# DSP_CM1 register map
Vendor: Texas Instruments
Peripheral module from a debugger description file (folder omap4430).
Registers are 32-bit, access per field, reset 0x3 unless marked. A register's access mark holds for its fields unless they carry their own. Offsets are as the file gives them; lines under a group give offsets from that group; [hi:lo] are bit positions; {n}, {i} and the like mark numbered series; 'fields as' and 'values as' point back to an identical list; <NAME> marks a mode.

## DSP_CM1
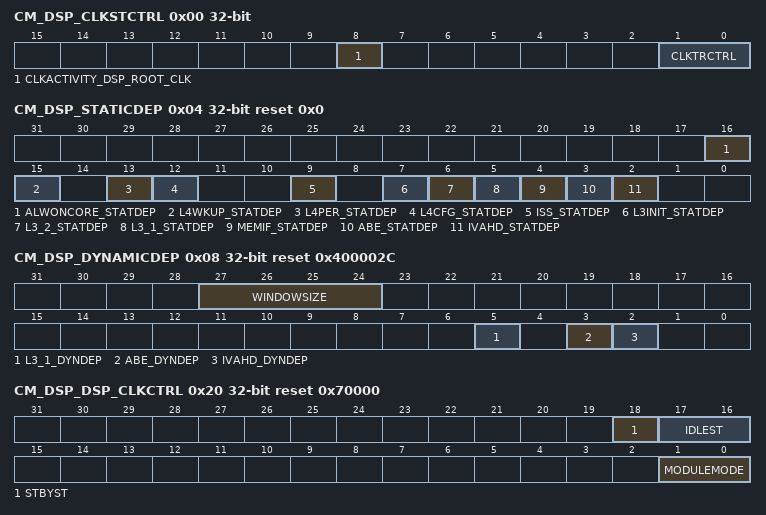
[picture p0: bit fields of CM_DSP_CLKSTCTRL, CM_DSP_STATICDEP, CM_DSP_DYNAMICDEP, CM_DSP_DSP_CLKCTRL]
0x00 CM_DSP_CLKSTCTRL — This register enables the DSP domain power state transition. It controls the hardware supervised domain power state transition between ON-ACTIVE and ON-INACTIVE states. It also holds 1 status bit per clock input of the domain.
  [8] CLKACTIVITY_DSP_ROOT_CLK ro — This field indicates the state of the DSP_ROOT_CLK clock in the domain. [warm reset insensitive]
    0=CLKACTIVITY_DSP_ROOT_CLK_0_r (Corresponding clock is definitely gated); 1=CLKACTIVITY_DSP_ROOT_CLK_1_r (Corresponding clock is running or gating/ungating transition is ongoing)
  [1:0] CLKTRCTRL rw — Controls the clock state transition of the DSP clock domain.
    0=NO_SLEEP: Sleep transition cannot be initiated. Wakeup transition may however occur.; 1=SW_SLEEP: Start a software forced sleep transition on the domain; 2=SW_WKUP: Start a software forced wake-up transition on the domain; 3=HW_AUTO: Automatic transition is enabled. Sleep and wakeup transition are based upon hardware conditions.
0x04 CM_DSP_STATICDEP reset 0x0 — This register controls the static domain depedencies from DSP domain towards 'target' domains. It is relevant only for domain having system initiator(s).
  [16] ALWONCORE_STATDEP ro — Static dependency towards ALWONCORE clock domain
    0=ALWONCORE_STATDEP_0_r (Dependency is disabled)
  [15] L4WKUP_STATDEP rw — Static dependency towards L4WKUP clock domain
    0=Dependency is disabled; 1=Dependency is enabled
  [13] L4PER_STATDEP rw — Static dependency towards L4PER clock domain
    0=Dependency is disabled; 1=Dependency is enabled
  [12] L4CFG_STATDEP rw — Static dependency towards L4CFG clock domain
    0=Dependency is disabled; 1=Dependency is enabled
  [9] ISS_STATDEP ro — Static dependency towards ISS clock domain
    0=ISS_STATDEP_0_r (Dependency is disabled)
  [7] L3INIT_STATDEP rw — Static dependency towards L3INIT clock domain
    0=Dependency is disabled; 1=Dependency is enabled
  [6] L3_2_STATDEP rw — Static dependency towards L3_2 clock domain
    0=Dependency is disabled; 1=Dependency is enabled
  [5] L3_1_STATDEP rw — Static dependency towards L3_1 clock domain
    0=Dependency is disabled; 1=Dependency is enabled
  [4] MEMIF_STATDEP rw — Static dependency towards MEMIF clock domain
    0=Dependency is disabled; 1=Dependency is enabled
  [3] ABE_STATDEP rw — Static dependency towards ABE clock domain
    0=Dependency is disabled; 1=Dependency is enabled
  [2] IVAHD_STATDEP rw — Static dependency towards IVAHD clock domain
    0=Dependency is disabled; 1=Dependency is enabled
0x08 CM_DSP_DYNAMICDEP access not given reset 0x400002C — This register controls the dynamic domain depedencies from DSP domain towards 'target' domains. It is relevant only for domain having INTRCONN master port(s).
  [27:24] WINDOWSIZE rw — Size of sliding window used to monitor INTRCONN interface activity for determination of auto-sleep feature. Time unit defined byCM_DYN_DEP_PRESCAL register.
  [5] L3_1_DYNDEP — Dynamic dependency towards L3_1 clock domain (access R Rreturns1s)
    1=L3_1_DYNDEP_1_r (Dependency is enabled)
  [3] ABE_DYNDEP — Dynamic dependency towards ABE clock domain (access R Rreturns1s)
    1=ABE_DYNDEP_1_r (Dependency is enabled)
  [2] IVAHD_DYNDEP — Dynamic dependency towards IVAHD clock domain (access R Rreturns1s)
    1=IVAHD_DYNDEP_1_r (Dependency is enabled)
0x20 CM_DSP_DSP_CLKCTRL reset 0x70000 — This register manages the DSP clocks.
  [18] STBYST ro — Module standby status. [warm reset insensitive]
    0=STBYST_0_r (Module is functional (not in standby)); 1=STBYST_1_r (Module is in standby)
  [17:16] IDLEST ro — Module idle status. [warm reset insensitive]
    0=IDLEST_0_r (Module is fully functional, including INTRCONN); 1=IDLEST_1_r (Module is performing transition: wakeup, or sleep, or sleep abortion); 2=IDLEST_2_r (Module is in Idle mode (only INTRCONN part). It is functional if using separate functional clock); 3=IDLEST_3_r (Module is disabled and cannot be accessed)
  [1:0] MODULEMODE rw — Control the way mandatory clocks are managed.
    0=Module is disable by software. Any INTRCONN access to module results in an error, except if resulting from a module wakeup (asynchronous wakeup).; 1=Module is managed automatically by hardware according to clock domain transition. A clock domain sleep transition put module into idle. A wakeup domain transition put it back into function. If CLKTRCTRL=3, any INTRCONN access to module is always granted. Module clocks may be gated according to the clock domain state.; 2=MODULEMODE_2_r (Reserved); 3=MODULEMODE_3_r (Reserved)
